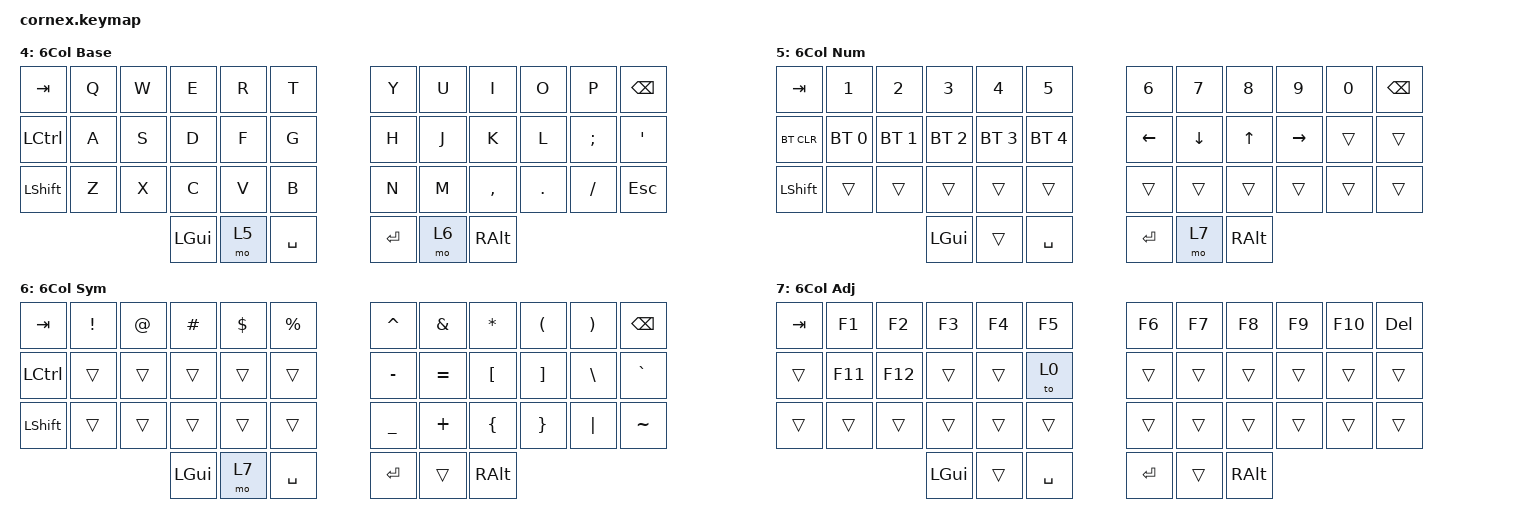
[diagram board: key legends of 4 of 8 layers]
/*
 * Copyright (c) 2020 The ZMK Contributors
 *
 * SPDX-License-Identifier: MIT
 */

#include <behaviors.dtsi>
#include <dt-bindings/zmk/keys.h>
#include <dt-bindings/zmk/bt.h>

/ {
	combos {
		compatible = "zmk,combos";
		
		combo_studio_unlock {
			timeout-ms = <50>;
			key-positions = <0 1>;
			bindings = <&studio_unlock>;
			layers = <0>;
		};
	};

	keymap {
		compatible = "zmk,keymap";

		// ===== 5-COLUMN LAYOUT (Default) =====
		default_layer {
			display-name = "5Col Base";
			matrix-transform = <&five_column_transform>;
			bindings = <
		//╭──────────┬──────────┬──────────┬──────────┬──────────╮   ╭──────────┬──────────┬──────────┬──────────┬──────────╮
		//│  Q       │  W       │  E       │  R       │  T       │   │  Y       │  U       │  I       │  O       │  P       │
			&kp Q      &kp W      &kp E      &kp R      &kp T          &kp Y      &kp U      &kp I      &kp O      &kp P
		//├──────────┼──────────┼──────────┼──────────┼──────────┤   ├──────────┼──────────┼──────────┼──────────┼──────────┤
		//│  A       │  S       │  D       │  F       │  G       │   │  H       │  J       │  K       │  L       │ ; :      │
			&kp A      &kp S      &kp D      &kp F      &kp G          &kp H      &kp J      &kp K      &kp L      &kp SEMI
		//├──────────┼──────────┼──────────┼──────────┼──────────┤   ├──────────┼──────────┼──────────┼──────────┼──────────┤
		//│  Z       │  X       │  C       │  V       │  B       │   │  N       │  M       │ , <      │ . >      │ / ?      │
			&kp Z      &kp X      &kp C      &kp V      &kp B          &kp N      &kp M      &kp COMMA  &kp DOT    &kp FSLH
		//╰──────────┴──────────┴──────────┼──────────┼──────────┼──────────┤   ├──────────┼──────────┼──────────┼──────────┴──────────┴──────────╯
											 &kp LGUI   &mo 1      &kp SPACE      &kp RET    &mo 2      &kp RALT
		//                                 ╰──────────┴──────────┴──────────╯   ╰──────────┴──────────┴──────────╯
			>;
		};

		lower_layer {
			display-name = "5Col Num";
			matrix-transform = <&five_column_transform>;
			bindings = <
		//╭──────────┬──────────┬──────────┬──────────┬──────────╮   ╭──────────┬──────────┬──────────┬──────────┬──────────╮
		//│  1       │  2       │  3       │  4       │  5       │   │  6       │  7       │  8       │  9       │  0       │
			&kp N1     &kp N2     &kp N3     &kp N4     &kp N5         &kp N6     &kp N7     &kp N8     &kp N9     &kp N0
		//├──────────┼──────────┼──────────┼──────────┼──────────┤   ├──────────┼──────────┼──────────┼──────────┼──────────┤
		//│ BT1      │ BT2      │ BT3      │ BT4      │ BT5      │   │ LEFT     │ DOWN     │ UP       │ RIGHT    │          │
		   &bt BT_SEL 0 &bt BT_SEL 1 &bt BT_SEL 2 &bt BT_SEL 3 &bt BT_SEL 4  &kp LEFT   &kp DOWN   &kp UP     &kp RIGHT  &trans
		//├──────────┼──────────┼──────────┼──────────┼──────────┤   ├──────────┼──────────┼──────────┼──────────┼──────────┤
		//│          │          │          │          │          │   │          │          │          │          │          │
			&trans     &trans     &trans     &trans     &trans         &trans     &trans     &trans     &trans     &trans
		//╰──────────┴──────────┴──────────┼──────────┼──────────┼──────────┤   ├──────────┼──────────┼──────────┼──────────┴──────────┴──────────╯
											 &kp LGUI   &trans     &kp SPACE      &kp RET    &mo 3      &kp RALT
		//                                 ╰──────────┴──────────┴──────────╯   ╰──────────┴──────────┴──────────╯
			>;
		};

		raise_layer {
			display-name = "5Col Sym";
			matrix-transform = <&five_column_transform>;
			bindings = <
		//╭──────────┬──────────┬──────────┬──────────┬──────────╮   ╭──────────┬──────────┬──────────┬──────────┬──────────╮
		//│  !       │  @       │  #       │  $       │  %       │   │  ^       │  &       │  *       │  (       │  )       │
			&kp EXCL   &kp AT     &kp HASH   &kp DLLR   &kp PRCNT      &kp CARET  &kp AMPS   &kp ASTRK  &kp LPAR   &kp RPAR
		//├──────────┼──────────┼──────────┼──────────┼──────────┤   ├──────────┼──────────┼──────────┼──────────┼──────────┤
		//│          │          │          │          │          │   │  -       │  =       │  [       │  ]       │  \       │
			&trans     &trans     &trans     &trans     &trans         &kp MINUS  &kp EQUAL  &kp LBKT   &kp RBKT   &kp BSLH
		//├──────────┼──────────┼──────────┼──────────┼──────────┤   ├──────────┼──────────┼──────────┼──────────┼──────────┤
		//│          │          │          │          │          │   │  _       │  +       │  {       │  }       │  |       │
			&trans     &trans     &trans     &trans     &trans         &kp UNDER  &kp PLUS   &kp LBRC   &kp RBRC   &kp PIPE
		//╰──────────┴──────────┴──────────┼──────────┼──────────┼──────────┤   ├──────────┼──────────┼──────────┼──────────┴──────────┴──────────╯
											 &kp LGUI   &mo 3      &kp SPACE      &kp RET    &trans     &kp RALT
		//                                 ╰──────────┴──────────┴──────────╯   ╰──────────┴──────────┴──────────╯
			>;
		};

		adjust_layer {
			display-name = "5Col Adj";
			matrix-transform = <&five_column_transform>;
			bindings = <
		//╭──────────┬──────────┬──────────┬──────────┬──────────╮   ╭──────────┬──────────┬──────────┬──────────┬──────────╮
		//│ F1       │  F2      │  F3      │  F4      │  F5      │   │  F6      │  F7      │  F8      │  F9      │  F10     │
			&kp F1     &kp F2     &kp F3     &kp F4     &kp F5         &kp F6     &kp F7     &kp F8     &kp F9     &kp F10
		//├──────────┼──────────┼──────────┼──────────┼──────────┤   ├──────────┼──────────┼──────────┼──────────┼──────────┤
		//│ F11      │ F12      │          │          │ TO 6COL  │   │          │          │          │          │          │
			&kp F11    &kp F12    &trans     &trans     &to 4          &trans     &trans     &trans     &trans     &trans
		//├──────────┼──────────┼──────────┼──────────┼──────────┤   ├──────────┼──────────┼──────────┼──────────┼──────────┤
		//│ BT CLR   │          │          │          │          │   │          │          │          │          │          │
		   &bt BT_CLR  &trans     &trans     &trans     &trans         &trans     &trans     &trans     &trans     &trans
		//╰──────────┴──────────┴──────────┼──────────┼──────────┼──────────┤   ├──────────┼──────────┼──────────┼──────────┴──────────┴──────────╯
											 &kp LGUI   &trans     &kp SPACE      &kp RET    &trans     &kp RALT
		//                                 ╰──────────┴──────────┴──────────╯   ╰──────────┴──────────┴──────────╯
			>;
		};

		// ===== 6-COLUMN LAYOUT (Alternative) =====
		six_col_default {
			display-name = "6Col Base";
			matrix-transform = <&default_transform>;
			bindings = <
		//╭──────────┬──────────┬──────────┬──────────┬──────────┬──────────╮   ╭──────────┬──────────┬──────────┬──────────┬──────────┬──────────╮
		//│  TAB     │  Q       │  W       │  E       │  R       │  T       │   │  Y       │  U       │  I       │  O       │  P       │  BSPC    │
			&kp TAB    &kp Q      &kp W      &kp E      &kp R      &kp T          &kp Y      &kp U      &kp I      &kp O      &kp P      &kp BSPC
		//├──────────┼──────────┼──────────┼──────────┼──────────┼──────────┤   ├──────────┼──────────┼──────────┼──────────┼──────────┼──────────┤
		//│  CTRL    │  A       │  S       │  D       │  F       │  G       │   │  H       │  J       │  K       │  L       │ ; :      │  ' "     │
			&kp LCTRL  &kp A      &kp S      &kp D      &kp F      &kp G          &kp H      &kp J      &kp K      &kp L      &kp SEMI   &kp SQT
		//├──────────┼──────────┼──────────┼──────────┼──────────┼──────────┤   ├──────────┼──────────┼──────────┼──────────┼──────────┼──────────┤
		//│  SHIFT   │  Z       │  X       │  C       │  V       │  B       │   │  N       │  M       │ , <      │ . >      │ / ?      │  ESC     │
			&kp LSHFT  &kp Z      &kp X      &kp C      &kp V      &kp B          &kp N      &kp M      &kp COMMA  &kp DOT    &kp FSLH   &kp ESC
		//╰──────────┴──────────┴──────────┼──────────┼──────────┼──────────┤   ├──────────┼──────────┼──────────┼──────────┴──────────┴──────────╯
											 &kp LGUI   &mo 5      &kp SPACE      &kp RET    &mo 6      &kp RALT
		//                                 ╰──────────┴──────────┴──────────╯   ╰──────────┴──────────┴──────────╯
			>;
		};

		six_col_lower {
			display-name = "6Col Num";
			matrix-transform = <&default_transform>;
			bindings = <
		//╭──────────┬──────────┬──────────┬──────────┬──────────┬──────────╮   ╭──────────┬──────────┬──────────┬──────────┬──────────┬──────────╮
		//│  TAB     │  1       │  2       │  3       │  4       │  5       │   │  6       │  7       │  8       │  9       │  0       │  BSPC    │
			&kp TAB    &kp N1     &kp N2     &kp N3     &kp N4     &kp N5         &kp N6     &kp N7     &kp N8     &kp N9     &kp N0     &kp BSPC
		//├──────────┼──────────┼──────────┼──────────┼──────────┼──────────┤   ├──────────┼──────────┼──────────┼──────────┼──────────┼──────────┤
		//│ BT CLR   │ BT1      │ BT2      │ BT3      │ BT4      │ BT5      │   │ LEFT     │ DOWN     │ UP       │ RIGHT    │          │          │
		   &bt BT_CLR &bt BT_SEL 0 &bt BT_SEL 1 &bt BT_SEL 2 &bt BT_SEL 3 &bt BT_SEL 4  &kp LEFT   &kp DOWN   &kp UP     &kp RIGHT  &trans     &trans
		//├──────────┼──────────┼──────────┼──────────┼──────────┼──────────┤   ├──────────┼──────────┼──────────┼──────────┼──────────┼──────────┤
		//│  SHIFT   │          │          │          │          │          │   │          │          │          │          │          │          │
			&kp LSHFT  &trans     &trans     &trans     &trans     &trans         &trans     &trans     &trans     &trans     &trans     &trans
		//╰──────────┴──────────┴──────────┼──────────┼──────────┼──────────┤   ├──────────┼──────────┼──────────┼──────────┴──────────┴──────────╯
											 &kp LGUI   &trans     &kp SPACE      &kp RET    &mo 7      &kp RALT
		//                                 ╰──────────┴──────────┴──────────╯   ╰──────────┴──────────┴──────────╯
			>;
		};

		six_col_raise {
			display-name = "6Col Sym";
			matrix-transform = <&default_transform>;
			bindings = <
		//╭──────────┬──────────┬──────────┬──────────┬──────────┬──────────╮   ╭──────────┬──────────┬──────────┬──────────┬──────────┬──────────╮
		//│  TAB     │  !       │  @       │  #       │  $       │  %       │   │  ^       │  &       │  *       │  (       │  )       │  BSPC    │
			&kp TAB    &kp EXCL   &kp AT     &kp HASH   &kp DLLR   &kp PRCNT      &kp CARET  &kp AMPS   &kp ASTRK  &kp LPAR   &kp RPAR   &kp BSPC
		//├──────────┼──────────┼──────────┼──────────┼──────────┼──────────┤   ├──────────┼──────────┼──────────┼──────────┼──────────┼──────────┤
		//│  CTRL    │          │          │          │          │          │   │  -       │  =       │  [       │  ]       │  \       │  `       │
			&kp LCTRL  &trans     &trans     &trans     &trans     &trans         &kp MINUS  &kp EQUAL  &kp LBKT   &kp RBKT   &kp BSLH   &kp GRAVE
		//├──────────┼──────────┼──────────┼──────────┼──────────┼──────────┤   ├──────────┼──────────┼──────────┼──────────┼──────────┼──────────┤
		//│  SHIFT   │          │          │          │          │          │   │  _       │  +       │  {       │  }       │  |       │  ~       │
			&kp LSHFT  &trans     &trans     &trans     &trans     &trans         &kp UNDER  &kp PLUS   &kp LBRC   &kp RBRC   &kp PIPE   &kp TILDE
		//╰──────────┴──────────┴──────────┼──────────┼──────────┼──────────┤   ├──────────┼──────────┼──────────┼──────────┴──────────┴──────────╯
											 &kp LGUI   &mo 7      &kp SPACE      &kp RET    &trans     &kp RALT
		//                                 ╰──────────┴──────────┴──────────╯   ╰──────────┴──────────┴──────────╯
			>;
		};

		six_col_adjust {
			display-name = "6Col Adj";
			matrix-transform = <&default_transform>;
			bindings = <
		//╭──────────┬──────────┬──────────┬──────────┬──────────┬──────────╮   ╭──────────┬──────────┬──────────┬──────────┬──────────┬──────────╮
		//│  TAB     │  F1      │  F2      │  F3      │  F4      │  F5      │   │  F6      │  F7      │  F8      │  F9      │  F10     │  DEL     │
			&kp TAB    &kp F1     &kp F2     &kp F3     &kp F4     &kp F5         &kp F6     &kp F7     &kp F8     &kp F9     &kp F10    &kp DEL
		//├──────────┼──────────┼──────────┼──────────┼──────────┼──────────┤   ├──────────┼──────────┼──────────┼──────────┼──────────┼──────────┤
		//│          │  F11     │  F12     │          │          │ TO 5COL  │   │          │          │          │          │          │          │
			&trans     &kp F11    &kp F12    &trans     &trans     &to 0          &trans     &trans     &trans     &trans     &trans     &trans
		//├──────────┼──────────┼──────────┼──────────┼──────────┼──────────┤   ├──────────┼──────────┼──────────┼──────────┼──────────┼──────────┤
		//│          │          │          │          │          │          │   │          │          │          │          │          │          │
			&trans     &trans     &trans     &trans     &trans     &trans         &trans     &trans     &trans     &trans     &trans     &trans
		//╰──────────┴──────────┴──────────┼──────────┼──────────┼──────────┤   ├──────────┼──────────┼──────────┼──────────┴──────────┴──────────╯
											 &kp LGUI   &trans     &kp SPACE      &kp RET    &trans     &kp RALT
		//                                 ╰──────────┴──────────┴──────────╯   ╰──────────┴──────────┴──────────╯
			>;
		};
	};
};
